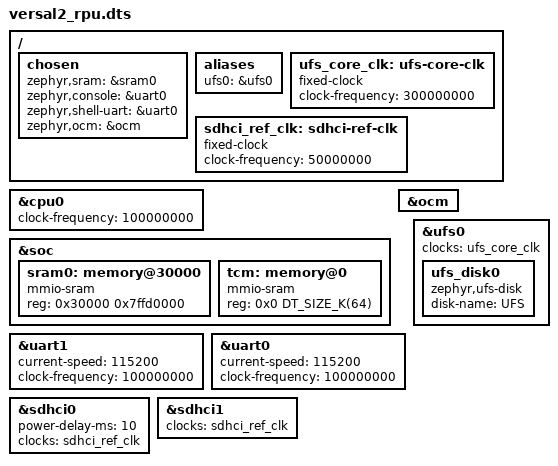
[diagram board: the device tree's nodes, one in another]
/*
 * Copyright (c) 2025, Advanced Micro Devices, Inc.
 *
 * SPDX-License-Identifier: Apache-2.0
 */

/dts-v1/;
#include <arm/xilinx/versal2_r52.dtsi>

/ {
	chosen {
		zephyr,sram = &sram0;
		zephyr,console = &uart0;
		zephyr,shell-uart = &uart0;
		zephyr,ocm = &ocm;
	};

	aliases {
		ufs0 = &ufs0;
	};

	ufs_core_clk: ufs-core-clk {
		compatible = "fixed-clock";
		clock-frequency = <300000000>;
		#clock-cells = <0>;
	};

	sdhci_ref_clk: sdhci-ref-clk {
		compatible = "fixed-clock";
		clock-frequency = <50000000>;
		#clock-cells = <0>;
	};
};

&cpu0 {
	clock-frequency = <100000000>;
};

&soc {
	sram0: memory@30000 {
		compatible = "mmio-sram";
		reg = <0x30000 0x7ffd0000>;
	};

	/* RPU-local TCM address (system address: 0xEBA00000) */
	tcm: memory@0 {
		compatible = "mmio-sram";
		reg = <0x0 DT_SIZE_K(64)>;
	};
};

&ocm {
	status = "okay";
};

&uart1 {
	status = "okay";
	current-speed = <115200>;
	clock-frequency = <100000000>;
};

&uart0 {
	status = "okay";
	current-speed = <115200>;
	clock-frequency = <100000000>;
};

&ufs0 {
	status = "okay";
	clocks = <&ufs_core_clk>;
	clock-names = "core";

	ufs_disk0 {
		compatible = "zephyr,ufs-disk";
		disk-name = "UFS";
		status = "okay";
	};
};

&sdhci0 {
	status = "okay";
	power-delay-ms = <10>;
	clocks = <&sdhci_ref_clk>;
};

&sdhci1 {
	status = "okay";
	clocks = <&sdhci_ref_clk>;
};
